# ADSP-SC83xW_HPC register map
Vendor: Analog Devices; Series: ADSP-SC83xW_HPC; File version: 3.0.3.517
CPU: 
Registers are 32-bit, read-write, reset 0x0 unless marked. A register's access mark holds for its fields unless they carry their own. Offsets are from the block's base; [hi:lo] are bit positions; {n}, {i} and the like mark numbered series; 'fields as' and 'values as' point back to an identical list.

## SPORT0 — Serial Port
Base 0x31002000
Same registers: SPORT1 0x31002100, SPORT2 0x31002200, SPORT3 0x31002300, SPORT4 0x31002400, SPORT5 0x31002500, SPORT6 0x31002600, SPORT7 0x31002700
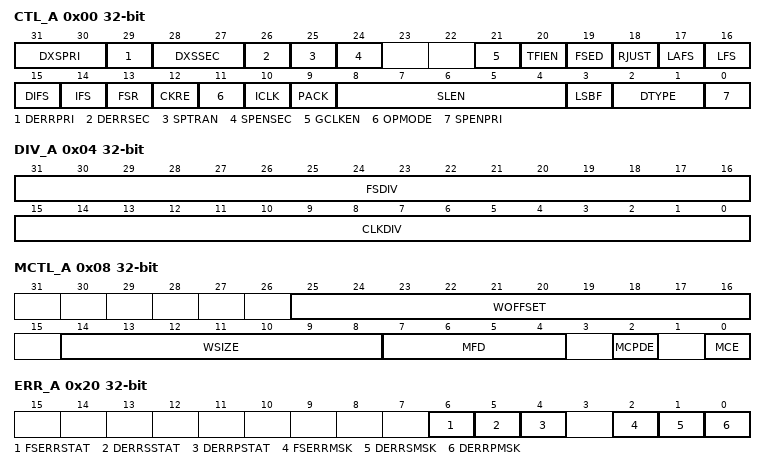
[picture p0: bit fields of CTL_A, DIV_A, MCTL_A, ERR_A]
0x00 CTL_A — Half SPORT 'A' Control Register
  [31:30] DXSPRI ro — Data Transfer Buffer Status (Primary)
    0=CTL_PRM_EMPTY (Empty); 2=CTL_PRM_PART_FULL (Partially full); 3=CTL_PRM_FULL (Full)
  [29] DERRPRI ro — Data Error Status (Primary)
    0=CTL_PRM_NO_ERR (No error); 1=CTL_PRM_ERR (Error (Tx underflow or Rx overflow))
  [28:27] DXSSEC ro — Data Transfer Buffer Status (Secondary)
    0=CTL_SEC_EMPTY (Empty); 2=CTL_SEC_PART_FULL (Partially full); 3=CTL_SEC_FULL (Full)
  [26] DERRSEC ro — Data Error Status (Secondary)
    0=CTL_SEC_NO_ERR (No error); 1=CTL_SEC_ERR (Error (Tx underflow or Rx overflow))
  [25] SPTRAN — Serial Port Transfer Direction
    0=CTL_RX (Receive); 1=CTL_TX (Transmit)
  [24] SPENSEC — Serial Port Enable (Secondary)
    0=CTL_SECONDARY_DIS (Disable); 1=CTL_SECONDARY_EN (Enable)
  [21] GCLKEN — Gated Clock Enable
    0=CTL_GCLK_DIS (Disable); 1=CTL_GCLK_EN (Enable)
  [20] TFIEN — Transmit Finish Interrupt Enable
    0=CTL_TXFIN_DIS (Last word sent (DMA count done) interrupt); 1=CTL_TXFIN_EN (Last bit sent (Tx buffer done) interrupt)
  [19] FSED — Frame Sync Edge Detect
    0=CTL_LEVEL_FS (Level detect frame sync); 1=CTL_EDGE_FS (Edge detect frame sync)
  [18] RJUST — Right-Justified Operation Mode
    0=CTL_RJUST_DIS (Disable); 1=CTL_RJUST_EN (Enable)
  [17] LAFS — Late Frame Sync / OPMODE2
    0=CTL_EARLY_FS (Early frame sync); 1=CTL_LATE_FS (Late frame sync)
  [16] LFS — Active-Low Frame Sync / L_FIRST / PLFS
    0=CTL_FS_LO (Active high frame sync (DSP standard mode)); 1=CTL_FS_HI (Active low frame sync (DSP standard mode))
  [15] DIFS — Data-Independent Frame Sync
    0=CTL_DATA_DEP_FS (Data-dependent frame sync); 1=CTL_DATA_INDP_FS (Data-independent frame sync)
  [14] IFS — Internal Frame Sync
    0=CTL_EXTERNAL_FS (External frame sync); 1=CTL_INTERNAL_FS (Internal frame sync)
  [13] FSR — Frame Sync Required
    0=CTL_FS_NOT_REQ (No frame sync required); 1=CTL_FS_REQ (Frame sync required)
  [12] CKRE — Clock Rising Edge
    0=CTL_CLK_FALL_EDGE (Clock falling edge); 1=CTL_CLK_RISE_EDGE (Clock rising edge)
  [11] OPMODE — Operation mode
    0=CTL_SERIAL_MC_MODE (DSP standard/multichannel mode); 1=CTL_I2S_MODE (I2S/packed/left-justified mode)
  [10] ICLK — Internal Clock
    0=CTL_EXTERNAL_CLK (External clock); 1=CTL_INTERNAL_CLK (Internal clock)
  [9] PACK — Packing Enable
    0=CTL_PACK_DIS (Disable); 1=CTL_PACK_EN (Enable)
  [8:4] SLEN range 0x00000000..0x0000001F — Serial Word Length
  [3] LSBF — Least-Significant Bit First
    0=CTL_MSB_FIRST (MSB first sent/received (big endian)); 1=CTL_LSB_FIRST (LSB first sent/received (little endian))
  [2:1] DTYPE — Data Type
    0=CTL_RJUSTIFY_ZFILL (Right-justify data, zero-fill unused MSBs); 1=CTL_RJUSTIFY_SFILL (Right-justify data, sign-extend unused MSBs); 2=CTL_USE_U_LAW (u-law compand data); 3=CTL_USE_A_LAW (A-law compand data)
  [0] SPENPRI — Serial Port Enable (Primary)
    0=CTL_DIS (Disable); 1=CTL_EN (Enable)
0x04 DIV_A — Half SPORT 'A' Divisor Register
  [31:16] FSDIV range 0x00000000..0x0000FFFF — Frame Sync Divisor
  [15:0] CLKDIV range 0x00000000..0x0000FFFF — Clock Divisor
0x08 MCTL_A — Half SPORT 'A' Multichannel Control Register
  [25:16] WOFFSET range 0x00000000..0x000003FF — Window Offset
  [14:8] WSIZE range 0x00000000..0x0000007F — Window Size
  [7:4] MFD range 0x00000000..0x0000000F — Multichannel Frame Delay
  [2] MCPDE — Multichannel Packing DMA Enable
    0=MCTL_MCPD_DIS (Disable); 1=MCTL_MCPD_EN (Enable)
  [0] MCE — Multichannel enable
    0=MCTL_DIS (Disable); 1=MCTL_EN (Enable)
{0xC+4i} CS{i}_A (i=0..3) — Half SPORT 'A' Multichannel {32i}-{32i+31} Select Register
  [31:0] VALUE range 0x00000000..0xFFFFFFFF — Channel Enable {32i}-{32i+31}
0x20 ERR_A — Half SPORT 'A' Error Register
  [6] FSERRSTAT — Frame Sync Error Status
  [5] DERRSSTAT — Data Error Secondary Status
  [4] DERRPSTAT — Data Error Primary Status
  [2] FSERRMSK — Frame Sync Error (Interrupt) Mask
  [1] DERRSMSK — Data Error Secondary (Interrupt) Mask
  [0] DERRPMSK — Data Error Primary (Interrupt) Mask
0x24 MSTAT_A — Half SPORT 'A' Multichannel Status Register
  [9:0] CURCHAN ro — Current Channel
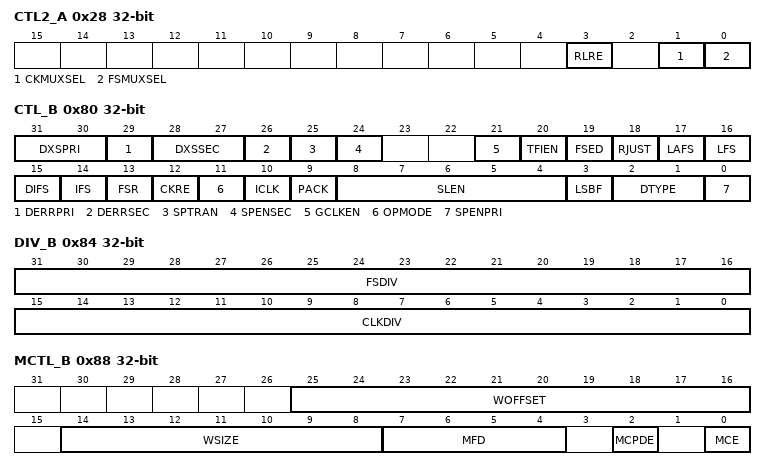
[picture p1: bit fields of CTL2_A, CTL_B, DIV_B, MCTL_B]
0x28 CTL2_A — Half SPORT 'A' Control 2 Register
  [3] RLRE range 0x00000000..0x00000001 — Receiver Late Sampling Enable
  [1] CKMUXSEL — Clock Multiplexer Select
    0=CTL2_CLK_MUX_DIS (Disable serial clock multiplexing); 1=CTL2_CLK_MUX_EN (Enable serial clock multiplexing)
  [0] FSMUXSEL — Frame Sync Multiplexer Select
    0=CTL2_FS_MUX_DIS (Disable frame sync multiplexing); 1=CTL2_FS_MUX_EN (Enable frame sync multiplexing)
0x40 TXPRI_A — Half SPORT 'A' Tx Buffer (Primary) Register
  [31:0] VALUE range 0x00000000..0xFFFFFFFF — Transmit Buffer (Primary)
0x44 RXPRI_A — Half SPORT 'A' Rx Buffer (Primary) Register
  [31:0] VALUE range 0x00000000..0xFFFFFFFF — Receive Buffer (Primary)
0x48 TXSEC_A — Half SPORT 'A' Tx Buffer (Secondary) Register
  [31:0] VALUE range 0x00000000..0xFFFFFFFF — Transmit Buffer (Secondary)
0x4C RXSEC_A — Half SPORT 'A' Rx Buffer (Secondary) Register
  [31:0] VALUE range 0x00000000..0xFFFFFFFF — Receive Buffer (Secondary)
0x80 CTL_B — Half SPORT 'B' Control Register
  [31:30] DXSPRI ro — Data Transfer Buffer Status (Primary)
  [29] DERRPRI ro — Data Error Status (Primary)
  [28:27] DXSSEC ro — Data Transfer Buffer Status (Secondary)
  [26] DERRSEC ro — Data Error Status (Secondary)
  [25] SPTRAN — Serial Port Transfer Direction
  [24] SPENSEC — Serial Port Enable (Secondary)
  [21] GCLKEN — Gated Clock Enable
  [20] TFIEN — Transmit Finish Interrupt Enable
  [19] FSED — Frame Sync Edge Detect
  [18] RJUST — Right-Justified Operation Mode
  [17] LAFS — Late Frame Sync / OPMODE2
  [16] LFS — Active-Low Frame Sync / L_FIRST / PLFS
  [15] DIFS — Data-Independent Frame Sync
  [14] IFS — Internal Frame Sync
  [13] FSR — Frame Sync Required
  [12] CKRE — Clock Rising Edge
  [11] OPMODE — Operation Mode
  [10] ICLK — Internal Clock
  [9] PACK — Packing Enable
  [8:4] SLEN range 0x00000000..0x0000001F — Serial Word Length
  [3] LSBF — Least-Significant Bit First
  [2:1] DTYPE — Data Type
  [0] SPENPRI — Serial Port Enable (Primary)
0x84 DIV_B — Half SPORT 'B' Divisor Register
  fields as DIV_A
0x88 MCTL_B — Half SPORT 'B' Multichannel Control Register
  [25:16] WOFFSET range 0x00000000..0x000003FF — Window Offset
  [14:8] WSIZE range 0x00000000..0x0000007F — Window Size
  [7:4] MFD range 0x00000000..0x0000000F — Multichannel Frame Delay
  [2] MCPDE — Multichannel Packing DMA Enable
  [0] MCE — Multichannel Enable
{0x8C+4i} CS{i}_B (i=0..3) — Half SPORT 'B' Multichannel {32i}-{32i+31} Select Register
  fields as CS0_A
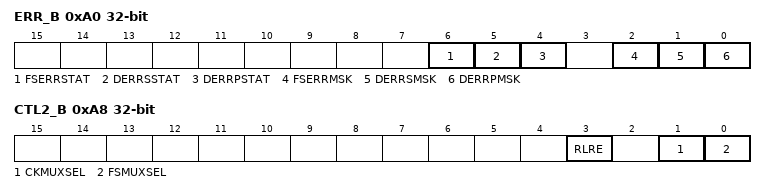
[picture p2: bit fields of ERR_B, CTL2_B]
0xA0 ERR_B — Half SPORT 'B' Error Register
  fields as ERR_A
0xA4 MSTAT_B — Half SPORT 'B' Multichannel Status Register
  [9:0] CURCHAN ro — Current Channel
0xA8 CTL2_B — Half SPORT 'B' Control 2 Register
  [3] RLRE range 0x00000000..0x00000001 — Receiver Late Reception Enable
  [1] CKMUXSEL — Clock Multiplexer Select
  [0] FSMUXSEL — Frame Sync Multiplexer Select
0xC0 TXPRI_B — Half SPORT 'B' Tx Buffer (Primary) Register
  fields as TXPRI_A
0xC4 RXPRI_B — Half SPORT 'B' Rx Buffer (Primary) Register
  [31:0] VALUE range 0x00000000..0xFFFFFFFF — Receive Buffer (Primary)
0xC8 TXSEC_B — Half SPORT 'B' Tx Buffer (Secondary) Register
  fields as TXSEC_A
0xCC RXSEC_B — Half SPORT 'B' Rx Buffer (Secondary) Register
  fields as RXSEC_A
